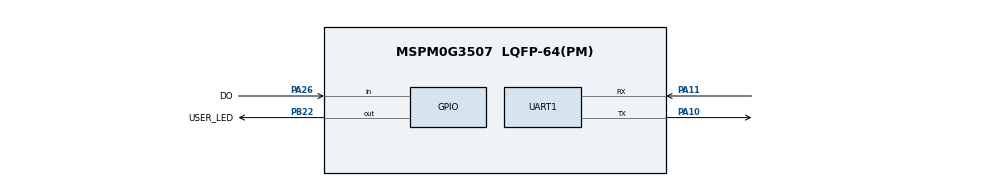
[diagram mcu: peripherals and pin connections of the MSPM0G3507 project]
//@cliArgs --device "MSPM0G350X" --package "LQFP-64(PM)" --part "Default"
//@v2CliArgs --device "MSPM0G3507" --package "LQFP-64(PM)"
//@cliArgs --rtos nortos
const ADC12 = scripting.addModule("/ti/driverlib/ADC12", {}, false);
const ADC0 = ADC12.addInstance();
const GPIO = scripting.addModule("/ti/driverlib/GPIO", {}, false);
const GPIO1 = GPIO.addInstance();
const GPIO2 = GPIO.addInstance();
const UART = scripting.addModule("/ti/driverlib/UART", {}, false);
const UART1 = UART.addInstance();
const SYSCTL = scripting.addModule("/ti/driverlib/SYSCTL");
ADC0.$name = "ADC_PHOTO";
ADC0.sampClkSrc = "DL_ADC12_CLOCK_ULPCLK";
ADC0.sampClkDiv = "DL_ADC12_CLOCK_DIVIDE_8";
ADC0.adcMem0chansel = "DL_ADC12_INPUT_CHAN_0";
ADC0.sampleTime0 = "10 us";
ADC0.enabledInterrupts = ["DL_ADC12_INTERRUPT_MEM0_RESULT_LOADED"];
ADC0.powerDownMode = "DL_ADC12_POWER_DOWN_MODE_MANUAL";
ADC0.peripheral.$assign = "ADC0";
ADC0.peripheral.adcPin0.$assign = "PA27";
GPIO1.$name = "GPIO_PHOTO";
GPIO1.port = "PORTA";
GPIO1.portSegment = "Upper";
GPIO1.associatedPins[0].$name = "DO";
GPIO1.associatedPins[0].direction = "INPUT";
GPIO1.associatedPins[0].internalResistor = "PULL_UP";
GPIO1.associatedPins[0].pin.$assign = "PA26";
GPIO2.$name = "GPIO_LED";
GPIO2.port = "PORTB";
GPIO2.portSegment = "Upper";
GPIO2.associatedPins[0].$name = "USER_LED";
GPIO2.associatedPins[0].direction = "OUTPUT";
GPIO2.associatedPins[0].initialValue = "CLEARED";
GPIO2.associatedPins[0].pin.$assign = "PB22";
UART1.$name = "UART_0";
UART1.enableFIFO = true;
UART1.rxFifoThreshold = "DL_UART_RX_FIFO_LEVEL_ONE_ENTRY";
UART1.txFifoThreshold = "DL_UART_TX_FIFO_LEVEL_3_4_EMPTY";
UART1.targetBaudRate = 115200;
UART1.enabledInterrupts = ["RX"];
UART1.peripheral.$assign = "UART0";
UART1.peripheral.rxPin.$assign = "PA11";
UART1.peripheral.txPin.$assign = "PA10";
SYSCTL.forceDefaultClkConfig = true;
